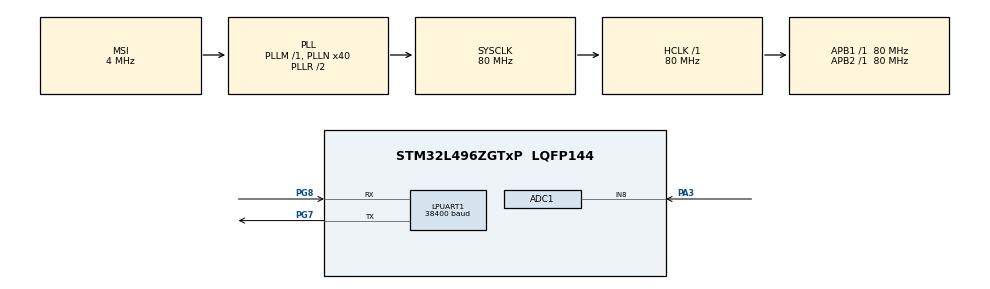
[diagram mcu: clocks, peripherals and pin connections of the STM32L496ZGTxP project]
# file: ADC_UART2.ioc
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ADC1.Channel-0\#ChannelRegularConversion=ADC_CHANNEL_8
ADC1.ContinuousConvMode=ENABLE
ADC1.NbrOfConversionFlag=1
ADC1.OffsetNumber-0\#ChannelRegularConversion=ADC_OFFSET_NONE
ADC1.Overrun=ADC_OVR_DATA_OVERWRITTEN
ADC1.OversamplingMode=DISABLE
ADC1.Rank-0\#ChannelRegularConversion=1
ADC1.Resolution=ADC_RESOLUTION_12B
ADC1.SamplingTime-0\#ChannelRegularConversion=ADC_SAMPLETIME_2CYCLES_5
ADC1.master=1
LPUART1.BaudRate=38400
LPUART1.WordLength=UART_WORDLENGTH_8B
Mcu.Family=STM32L4
Mcu.Name=STM32L496ZGTxP
Mcu.Package=LQFP144
NVIC.LPUART1_IRQn=true\:0\:0\:false\:false\:true\:true\:true\:true
NVIC.PriorityGroup=NVIC_PRIORITYGROUP_4
PA13\ (JTMS/SWDIO).Mode=Serial_Wire
PA13\ (JTMS/SWDIO).Signal=SYS_JTMS-SWDIO
PA14\ (JTCK/SWCLK).Mode=Serial_Wire
PA14\ (JTCK/SWCLK).Signal=SYS_JTCK-SWCLK
PA3.Signal=ADCx_IN8
PA5.Signal=ADCx_IN10
PC14-OSC32_IN\ (PC14).Mode=LSE-External-Oscillator
PC14-OSC32_IN\ (PC14).Signal=RCC_OSC32_IN
PC15-OSC32_OUT\ (PC15).Mode=LSE-External-Oscillator
PC15-OSC32_OUT\ (PC15).Signal=RCC_OSC32_OUT
PG7.Mode=Asynchronous
PG7.Signal=LPUART1_TX
PG8.Mode=Asynchronous
PG8.Signal=LPUART1_RX
ProjectManager.HeapSize=0x200
ProjectManager.StackSize=0x400
ProjectManager.TargetToolchain=STM32CubeIDE
RCC.ADCFreq_Value=48000000
RCC.AHBFreq_Value=80000000
RCC.APB1Freq_Value=80000000
RCC.APB1TimFreq_Value=80000000
RCC.APB2Freq_Value=80000000
RCC.APB2TimFreq_Value=80000000
RCC.CortexFreq_Value=80000000
RCC.HCLKFreq_Value=80000000
RCC.HSE_VALUE=8000000
RCC.HSI48_VALUE=48000000
RCC.HSI_VALUE=16000000
RCC.MSI_VALUE=4000000
RCC.PLLN=40
RCC.PLLSAI1N=24
RCC.SYSCLKFreq_VALUE=80000000
RCC.SYSCLKSource=RCC_SYSCLKSOURCE_PLLCLK
RCC.USBFreq_Value=48000000
RCC.VCOOutputFreq_Value=160000000
SH.ADCx_IN10.0=ADC1_IN10
SH.ADCx_IN8.0=ADC1_IN8,IN8-Single-Ended
board=custom

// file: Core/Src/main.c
/* USER CODE BEGIN Header */
/**
  ******************************************************************************
  * @file           : main.c
  * @brief          : Main program body
  ******************************************************************************
  * @attention
  *
  * Copyright (c) 2022 STMicroelectronics.
  * All rights reserved.
  *
  * This software is licensed under terms that can be found in the LICENSE file
  * in the root directory of this software component.
  * If no LICENSE file comes with this software, it is provided AS-IS.
  *
  ******************************************************************************
  */
/* USER CODE END Header */
#include "main.h"

/* USER CODE BEGIN Includes */
#include "gps.h"
#include "lora.h"
#include <stdio.h>
#include <stdlib.h>
#include <string.h>

/* USER CODE END Includes */

 ADC_HandleTypeDef hadc1;

UART_HandleTypeDef hlpuart1;

/* USER CODE BEGIN PV */

#define UART &hlpuart1

/* USER CODE END PV */

void SystemClock_Config(void);
static void MX_GPIO_Init(void);
static void MX_LPUART1_UART_Init(void);
static void MX_ADC1_Init(void);
/* USER CODE BEGIN PFP */

#define ADC_BUF_LEN 4096

/* USER CODE END PFP */

/* USER CODE BEGIN 0 */

void Send_Uart (char *string)
{
	HAL_UART_Transmit(UART, (uint8_t *)string, strlen (string), HAL_MAX_DELAY);
}

/* USER CODE END 0 */

int main(void)
{

  /* MCU Configuration--------------------------------------------------------*/

  /* Reset of all peripherals, Initializes the Flash interface and the Systick. */
  HAL_Init();

  /* Configure the system clock */
  SystemClock_Config();

  /* Initialize all configured peripherals */
  MX_GPIO_Init();
  MX_LPUART1_UART_Init();
  MX_ADC1_Init();
  /* USER CODE BEGIN 2 */

  //uint8_t ADCValue;

	int value;
	char string[11];

  /* USER CODE END 2 */

  /* Infinite loop */
  while (1)
  {

	  HAL_ADC_Start(&hadc1);
	  if(HAL_ADC_PollForConversion(&hadc1, 5) == HAL_OK)
	  {
		  value = HAL_ADC_GetValue(&hadc1);

		  if(value > 500){
			  itoa(value,string,10);
			  Send_Uart(string);
			  Send_Uart("\n");
		  }
	  }
	  HAL_Delay(200);

  }
}

void SystemClock_Config(void)
{
  RCC_OscInitTypeDef RCC_OscInitStruct = {0};
  RCC_ClkInitTypeDef RCC_ClkInitStruct = {0};

  /** Configure the main internal regulator output voltage
  */
  if (HAL_PWREx_ControlVoltageScaling(PWR_REGULATOR_VOLTAGE_SCALE1) != HAL_OK)
  {
    Error_Handler();
  }

  /** Initializes the RCC Oscillators according to the specified parameters
  * in the RCC_OscInitTypeDef structure.
  */
  RCC_OscInitStruct.OscillatorType = RCC_OSCILLATORTYPE_MSI;
  RCC_OscInitStruct.MSIState = RCC_MSI_ON;
  RCC_OscInitStruct.MSICalibrationValue = 0;
  RCC_OscInitStruct.MSIClockRange = RCC_MSIRANGE_6;
  RCC_OscInitStruct.PLL.PLLState = RCC_PLL_ON;
  RCC_OscInitStruct.PLL.PLLSource = RCC_PLLSOURCE_MSI;
  RCC_OscInitStruct.PLL.PLLM = 1;
  RCC_OscInitStruct.PLL.PLLN = 40;
  RCC_OscInitStruct.PLL.PLLP = RCC_PLLP_DIV2;
  RCC_OscInitStruct.PLL.PLLQ = RCC_PLLQ_DIV2;
  RCC_OscInitStruct.PLL.PLLR = RCC_PLLR_DIV2;
  if (HAL_RCC_OscConfig(&RCC_OscInitStruct) != HAL_OK)
  {
    Error_Handler();
  }

  /** Initializes the CPU, AHB and APB buses clocks
  */
  RCC_ClkInitStruct.ClockType = RCC_CLOCKTYPE_HCLK|RCC_CLOCKTYPE_SYSCLK
                              |RCC_CLOCKTYPE_PCLK1|RCC_CLOCKTYPE_PCLK2;
  RCC_ClkInitStruct.SYSCLKSource = RCC_SYSCLKSOURCE_PLLCLK;
  RCC_ClkInitStruct.AHBCLKDivider = RCC_SYSCLK_DIV1;
  RCC_ClkInitStruct.APB1CLKDivider = RCC_HCLK_DIV1;
  RCC_ClkInitStruct.APB2CLKDivider = RCC_HCLK_DIV1;

  if (HAL_RCC_ClockConfig(&RCC_ClkInitStruct, FLASH_LATENCY_4) != HAL_OK)
  {
    Error_Handler();
  }
}

static void MX_ADC1_Init(void)
{

  ADC_MultiModeTypeDef multimode = {0};
  ADC_ChannelConfTypeDef sConfig = {0};

  /** Common config
  */
  hadc1.Instance = ADC1;
  hadc1.Init.ClockPrescaler = ADC_CLOCK_ASYNC_DIV1;
  hadc1.Init.Resolution = ADC_RESOLUTION_12B;
  hadc1.Init.DataAlign = ADC_DATAALIGN_RIGHT;
  hadc1.Init.ScanConvMode = ADC_SCAN_DISABLE;
  hadc1.Init.EOCSelection = ADC_EOC_SINGLE_CONV;
  hadc1.Init.LowPowerAutoWait = DISABLE;
  hadc1.Init.ContinuousConvMode = ENABLE;
  hadc1.Init.NbrOfConversion = 1;
  hadc1.Init.DiscontinuousConvMode = DISABLE;
  hadc1.Init.ExternalTrigConv = ADC_SOFTWARE_START;
  hadc1.Init.ExternalTrigConvEdge = ADC_EXTERNALTRIGCONVEDGE_NONE;
  hadc1.Init.DMAContinuousRequests = DISABLE;
  hadc1.Init.Overrun = ADC_OVR_DATA_OVERWRITTEN;
  hadc1.Init.OversamplingMode = DISABLE;
  if (HAL_ADC_Init(&hadc1) != HAL_OK)
  {
    Error_Handler();
  }

  /** Configure the ADC multi-mode
  */
  multimode.Mode = ADC_MODE_INDEPENDENT;
  if (HAL_ADCEx_MultiModeConfigChannel(&hadc1, &multimode) != HAL_OK)
  {
    Error_Handler();
  }

  /** Configure Regular Channel
  */
  sConfig.Channel = ADC_CHANNEL_8;
  sConfig.Rank = ADC_REGULAR_RANK_1;
  sConfig.SamplingTime = ADC_SAMPLETIME_2CYCLES_5;
  sConfig.SingleDiff = ADC_SINGLE_ENDED;
  sConfig.OffsetNumber = ADC_OFFSET_NONE;
  sConfig.Offset = 0;
  if (HAL_ADC_ConfigChannel(&hadc1, &sConfig) != HAL_OK)
  {
    Error_Handler();
  }

}

static void MX_LPUART1_UART_Init(void)
{

  hlpuart1.Instance = LPUART1;
  hlpuart1.Init.BaudRate = 38400;
  hlpuart1.Init.WordLength = UART_WORDLENGTH_8B;
  hlpuart1.Init.StopBits = UART_STOPBITS_1;
  hlpuart1.Init.Parity = UART_PARITY_NONE;
  hlpuart1.Init.Mode = UART_MODE_TX_RX;
  hlpuart1.Init.HwFlowCtl = UART_HWCONTROL_NONE;
  hlpuart1.Init.OneBitSampling = UART_ONE_BIT_SAMPLE_DISABLE;
  hlpuart1.AdvancedInit.AdvFeatureInit = UART_ADVFEATURE_NO_INIT;
  if (HAL_UART_Init(&hlpuart1) != HAL_OK)
  {
    Error_Handler();
  }

}

static void MX_GPIO_Init(void)
{

  /* GPIO Ports Clock Enable */
  __HAL_RCC_GPIOC_CLK_ENABLE();
  __HAL_RCC_GPIOA_CLK_ENABLE();
  __HAL_RCC_GPIOG_CLK_ENABLE();
  HAL_PWREx_EnableVddIO2();

}

void Error_Handler(void)
{
  __disable_irq();
  while (1)
  {
  }
}
